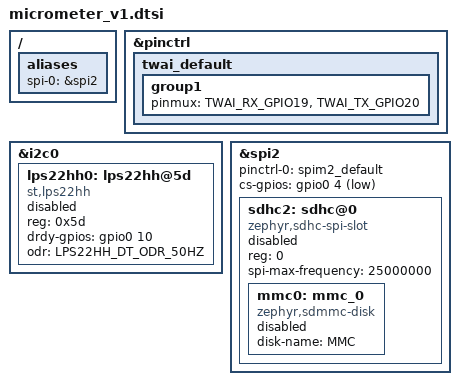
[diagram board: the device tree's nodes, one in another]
/*
 * Copyright (c) 2025-2026 Auxspace e.V.
 *
 * SPDX-License-Identifier: Apache-2.0
 *
 * µMETER revision 1 hardware:
 *   - SPI-attached SD card (zephyr,sdhc-spi-slot on spi2)
 *   - LSM6DSO32 IMU + LPS22HH barometer on i2c0
 */

/ {
	aliases {
		spi-0 = &spi2;
	};
};

&pinctrl {
	twai_default: twai_default {
		group1 {
			pinmux = <TWAI_RX_GPIO19>,
				 <TWAI_TX_GPIO20>;
		};
	};
};

&i2c0 {
	lps22hh0: lps22hh@5d {
		compatible = "st,lps22hh";
		reg = <0x5d>;
		drdy-gpios = <&gpio0 10 GPIO_ACTIVE_HIGH>;
		odr = <LPS22HH_DT_ODR_50HZ>;
		status = "disabled";
	};
};

&spi2 {
	#address-cells = <1>;
	#size-cells = <0>;
	pinctrl-0 = <&spim2_default>;
	pinctrl-names = "default";

	cs-gpios = <&gpio0 4 GPIO_ACTIVE_LOW>;

	sdhc2: sdhc@0 {
		compatible = "zephyr,sdhc-spi-slot";
		reg = <0>;
		spi-max-frequency = <25000000>;
		status = "disabled";

		mmc0: mmc_0 {
			compatible = "zephyr,sdmmc-disk";
			disk-name = "MMC";
			status = "disabled";
		};
	};
};
